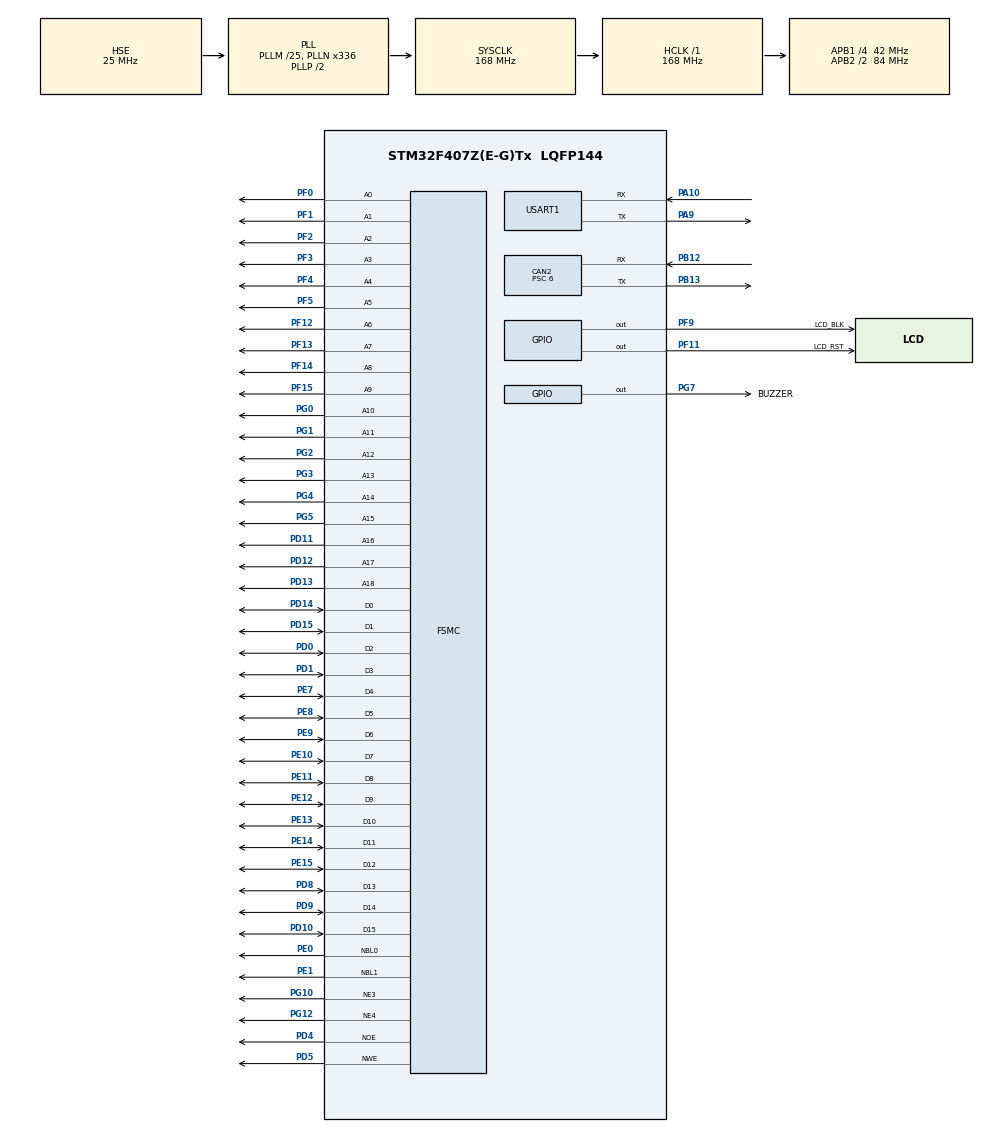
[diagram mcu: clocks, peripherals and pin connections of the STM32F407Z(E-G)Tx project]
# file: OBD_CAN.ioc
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CAN2.BS1=CAN_BS1_9TQ
CAN2.BS2=CAN_BS2_4TQ
CAN2.CalculateBaudRate=500000
CAN2.CalculateTimeBit=2000
CAN2.CalculateTimeQuantum=142.85714285714286
CAN2.Prescaler=6
Dma.MEMTOMEM.0.Direction=DMA_MEMORY_TO_MEMORY
Dma.MEMTOMEM.0.FIFOMode=DMA_FIFOMODE_ENABLE
Dma.MEMTOMEM.0.FIFOThreshold=DMA_FIFO_THRESHOLD_FULL
Dma.MEMTOMEM.0.Instance=DMA2_Stream0
Dma.MEMTOMEM.0.MemBurst=DMA_MBURST_SINGLE
Dma.MEMTOMEM.0.MemDataAlignment=DMA_MDATAALIGN_HALFWORD
Dma.MEMTOMEM.0.MemInc=DMA_MINC_DISABLE
Dma.MEMTOMEM.0.Mode=DMA_NORMAL
Dma.MEMTOMEM.0.PeriphBurst=DMA_PBURST_SINGLE
Dma.MEMTOMEM.0.PeriphDataAlignment=DMA_PDATAALIGN_HALFWORD
Dma.MEMTOMEM.0.PeriphInc=DMA_PINC_ENABLE
Dma.MEMTOMEM.0.Priority=DMA_PRIORITY_VERY_HIGH
Dma.Request0=MEMTOMEM
FSMC.AddressSetupTime3=5
FSMC.AddressSetupTime4=2
FSMC.BusTurnAroundDuration3=5
FSMC.BusTurnAroundDuration4=1
FSMC.DataSetupTime3=5
FSMC.DataSetupTime4=6
FSMC.WriteOperation4=FSMC_WRITE_OPERATION_ENABLE
Mcu.Family=STM32F4
Mcu.Name=STM32F407Z(E-G)Tx
Mcu.Package=LQFP144
NVIC.CAN2_RX0_IRQn=true\:5\:0\:true\:false\:true\:true\:true\:true
NVIC.CAN2_SCE_IRQn=true\:5\:0\:true\:false\:true\:true\:true\:true
NVIC.DMA2_Stream0_IRQn=true\:5\:0\:true\:false\:true\:true\:true\:true
NVIC.PriorityGroup=NVIC_PRIORITYGROUP_4
NVIC.TIM6_DAC_IRQn=true\:15\:0\:false\:false\:true\:false\:true\:true
NVIC.TimeBase=TIM6_DAC_IRQn
NVIC.TimeBaseIP=TIM6
PA10.Mode=Asynchronous
PA10.Signal=USART1_RX
PA13.Mode=Serial_Wire
PA13.Signal=SYS_JTMS-SWDIO
PA14.Mode=Serial_Wire
PA14.Signal=SYS_JTCK-SWCLK
PA9.Mode=Asynchronous
PA9.Signal=USART1_TX
PB12.Mode=CAN_Activate
PB12.Signal=CAN2_RX
PB13.Mode=CAN_Activate
PB13.Signal=CAN2_TX
PD0.Signal=FSMC_D2_DA2
PD1.Signal=FSMC_D3_DA3
PD10.Signal=FSMC_D15_DA15
PD11.Signal=FSMC_A16_CLE
PD12.Signal=FSMC_A17_ALE
PD13.Signal=FSMC_A18
PD14.Signal=FSMC_D0_DA0
PD15.Signal=FSMC_D1_DA1
PD4.Signal=FSMC_NOE
PD5.Signal=FSMC_NWE
PD8.Signal=FSMC_D13_DA13
PD9.Signal=FSMC_D14_DA14
PE0.Signal=FSMC_NBL0
PE1.Signal=FSMC_NBL1
PE10.Signal=FSMC_D7_DA7
PE11.Signal=FSMC_D8_DA8
PE12.Signal=FSMC_D9_DA9
PE13.Signal=FSMC_D10_DA10
PE14.Signal=FSMC_D11_DA11
PE15.Signal=FSMC_D12_DA12
PE7.Signal=FSMC_D4_DA4
PE8.Signal=FSMC_D5_DA5
PE9.Signal=FSMC_D6_DA6
PF0.Signal=FSMC_A0
PF1.Signal=FSMC_A1
PF11.GPIO_Label=LCD_RST
PF11.Signal=GPIO_Output
PF12.Signal=FSMC_A6
PF13.Signal=FSMC_A7
PF14.Signal=FSMC_A8
PF15.Signal=FSMC_A9
PF2.Signal=FSMC_A2
PF3.Signal=FSMC_A3
PF4.Signal=FSMC_A4
PF5.Signal=FSMC_A5
PF9.GPIO_Label=LCD_BLK
PF9.Signal=GPIO_Output
PG0.Signal=FSMC_A10
PG1.Signal=FSMC_A11
PG10.Mode=NorPsramChipSelect3_3
PG10.Signal=FSMC_NE3
PG12.Mode=NorPsramChipSelect4_4
PG12.Signal=FSMC_NE4
PG2.Signal=FSMC_A12
PG3.Signal=FSMC_A13
PG4.Signal=FSMC_A14
PG5.Signal=FSMC_A15
PG7.GPIO_Label=BUZZER
PG7.Signal=GPIO_Output
PH0-OSC_IN.Mode=HSE-External-Oscillator
PH0-OSC_IN.Signal=RCC_OSC_IN
PH1-OSC_OUT.Mode=HSE-External-Oscillator
PH1-OSC_OUT.Signal=RCC_OSC_OUT
ProjectManager.HeapSize=0x1000
ProjectManager.StackSize=0x1000
ProjectManager.TargetToolchain=MDK-ARM V5.32
RCC.48MHZClocksFreq_Value=84000000
RCC.AHBFreq_Value=168000000
RCC.APB1CLKDivider=RCC_HCLK_DIV4
RCC.APB1Freq_Value=42000000
RCC.APB1TimFreq_Value=84000000
RCC.APB2CLKDivider=RCC_HCLK_DIV2
RCC.APB2Freq_Value=84000000
RCC.APB2TimFreq_Value=168000000
RCC.CortexFreq_Value=168000000
RCC.HCLKFreq_Value=168000000
RCC.HSE_VALUE=25000000
RCC.HSI_VALUE=16000000
RCC.LSE_VALUE=32768
RCC.PLLM=25
RCC.PLLN=336
RCC.PLLSourceVirtual=RCC_PLLSOURCE_HSE
RCC.SYSCLKFreq_VALUE=168000000
RCC.SYSCLKSource=RCC_SYSCLKSOURCE_PLLCLK
RCC.VCOOutputFreq_Value=336000000
SH.FSMC_A0.0=FSMC_A0,A0_3
SH.FSMC_A0.1=FSMC_A0,19b-a4
SH.FSMC_A1.0=FSMC_A1,19b-a4
SH.FSMC_A10.0=FSMC_A10,19b-a4
SH.FSMC_A11.0=FSMC_A11,19b-a4
SH.FSMC_A12.0=FSMC_A12,19b-a4
SH.FSMC_A13.0=FSMC_A13,19b-a4
SH.FSMC_A14.0=FSMC_A14,19b-a4
SH.FSMC_A15.0=FSMC_A15,19b-a4
SH.FSMC_A16_CLE.0=FSMC_A16,19b-a4
SH.FSMC_A17_ALE.0=FSMC_A17,19b-a4
SH.FSMC_A18.0=FSMC_A18,19b-a4
SH.FSMC_A2.0=FSMC_A2,19b-a4
SH.FSMC_A3.0=FSMC_A3,19b-a4
SH.FSMC_A4.0=FSMC_A4,19b-a4
SH.FSMC_A5.0=FSMC_A5,19b-a4
SH.FSMC_A6.0=FSMC_A6,19b-a4
SH.FSMC_A7.0=FSMC_A7,19b-a4
SH.FSMC_A8.0=FSMC_A8,19b-a4
SH.FSMC_A9.0=FSMC_A9,19b-a4
SH.FSMC_D0_DA0.0=FSMC_D0,16b-d3
SH.FSMC_D0_DA0.1=FSMC_D0,16b-d4
SH.FSMC_D10_DA10.0=FSMC_D10,16b-d3
SH.FSMC_D10_DA10.1=FSMC_D10,16b-d4
SH.FSMC_D11_DA11.0=FSMC_D11,16b-d3
SH.FSMC_D11_DA11.1=FSMC_D11,16b-d4
SH.FSMC_D12_DA12.0=FSMC_D12,16b-d3
SH.FSMC_D12_DA12.1=FSMC_D12,16b-d4
SH.FSMC_D13_DA13.0=FSMC_D13,16b-d3
SH.FSMC_D13_DA13.1=FSMC_D13,16b-d4
SH.FSMC_D14_DA14.0=FSMC_D14,16b-d3
SH.FSMC_D14_DA14.1=FSMC_D14,16b-d4
SH.FSMC_D15_DA15.0=FSMC_D15,16b-d3
SH.FSMC_D15_DA15.1=FSMC_D15,16b-d4
SH.FSMC_D1_DA1.0=FSMC_D1,16b-d3
SH.FSMC_D1_DA1.1=FSMC_D1,16b-d4
SH.FSMC_D2_DA2.0=FSMC_D2,16b-d3
SH.FSMC_D2_DA2.1=FSMC_D2,16b-d4
SH.FSMC_D3_DA3.0=FSMC_D3,16b-d3
SH.FSMC_D3_DA3.1=FSMC_D3,16b-d4
SH.FSMC_D4_DA4.0=FSMC_D4,16b-d3
SH.FSMC_D4_DA4.1=FSMC_D4,16b-d4
SH.FSMC_D5_DA5.0=FSMC_D5,16b-d3
SH.FSMC_D5_DA5.1=FSMC_D5,16b-d4
SH.FSMC_D6_DA6.0=FSMC_D6,16b-d3
SH.FSMC_D6_DA6.1=FSMC_D6,16b-d4
SH.FSMC_D7_DA7.0=FSMC_D7,16b-d3
SH.FSMC_D7_DA7.1=FSMC_D7,16b-d4
SH.FSMC_D8_DA8.0=FSMC_D8,16b-d3
SH.FSMC_D8_DA8.1=FSMC_D8,16b-d4
SH.FSMC_D9_DA9.0=FSMC_D9,16b-d3
SH.FSMC_D9_DA9.1=FSMC_D9,16b-d4
SH.FSMC_NBL0.0=FSMC_NBL0,2ByteEnable4
SH.FSMC_NBL1.0=FSMC_NBL1,2ByteEnable4
SH.FSMC_NOE.0=FSMC_NOE,Lcd3
SH.FSMC_NOE.1=FSMC_NOE,Sram4
SH.FSMC_NWE.0=FSMC_NWE,Lcd3
SH.FSMC_NWE.1=FSMC_NWE,Sram4
USART1.VirtualMode=VM_ASYNC
VP_SYS_VS_tim6.Mode=TIM6
board=custom

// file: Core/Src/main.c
/* USER CODE BEGIN Header */
// ... ���һЩ�ļ�ͷ˵�� ...
/* USER CODE END Header */
#include "main.h"
#include "can.h"
#include "dma.h"
#include "usart.h"
#include "gpio.h"
#include "fsmc.h"
/* USER CODE BEGIN Includes */
#include "app_system.h" //
#include <stdio.h>
/* USER CODE END Includes */

/* USER CODE BEGIN PTD */
int fputc(int ch, FILE *f)
{
    HAL_UART_Transmit(&huart1, (uint8_t *)&ch, 1, HAL_MAX_DELAY);
    return ch;
}
/* USER CODE END PTD */

/* USER CODE BEGIN PFP */
void SystemClock_Config(void);
/* USER CODE END PFP */

int main(void)
{
  /* MCU Configuration--------------------------------------------------------*/
  HAL_Init();
  SystemClock_Config();

  /* Initialize all configured peripherals */
  MX_GPIO_Init();
  MX_DMA_Init();
  MX_USART1_UART_Init();  // 串口在这里才初始化成功！
  MX_FSMC_Init();
  MX_CAN2_Init();

  /* USER CODE BEGIN 2 */

  App_System_Init();
  vTaskStartScheduler();
  /* USER CODE END 2 */

  /* Infinite loop */
  while (1)
  {
  }
}
void SystemClock_Config(void)
{
  RCC_OscInitTypeDef RCC_OscInitStruct = {0};
  RCC_ClkInitTypeDef RCC_ClkInitStruct = {0};

  /** Configure the main internal regulator output voltage
  */
  __HAL_RCC_PWR_CLK_ENABLE();
  __HAL_PWR_VOLTAGESCALING_CONFIG(PWR_REGULATOR_VOLTAGE_SCALE1);

  /** Initializes the RCC Oscillators according to the specified parameters
  * in the RCC_OscInitTypeDef structure.
  */
  RCC_OscInitStruct.OscillatorType = RCC_OSCILLATORTYPE_HSE;
  RCC_OscInitStruct.HSEState = RCC_HSE_ON;
  RCC_OscInitStruct.PLL.PLLState = RCC_PLL_ON;
  RCC_OscInitStruct.PLL.PLLSource = RCC_PLLSOURCE_HSE;
  RCC_OscInitStruct.PLL.PLLM = 25;
  RCC_OscInitStruct.PLL.PLLN = 336;
  RCC_OscInitStruct.PLL.PLLP = RCC_PLLP_DIV2;
  RCC_OscInitStruct.PLL.PLLQ = 4;
  if (HAL_RCC_OscConfig(&RCC_OscInitStruct) != HAL_OK)
  {
    Error_Handler();
  }

  /** Initializes the CPU, AHB and APB buses clocks
  */
  RCC_ClkInitStruct.ClockType = RCC_CLOCKTYPE_HCLK|RCC_CLOCKTYPE_SYSCLK
                              |RCC_CLOCKTYPE_PCLK1|RCC_CLOCKTYPE_PCLK2;
  RCC_ClkInitStruct.SYSCLKSource = RCC_SYSCLKSOURCE_PLLCLK;
  RCC_ClkInitStruct.AHBCLKDivider = RCC_SYSCLK_DIV1;
  RCC_ClkInitStruct.APB1CLKDivider = RCC_HCLK_DIV4;
  RCC_ClkInitStruct.APB2CLKDivider = RCC_HCLK_DIV2;

  if (HAL_RCC_ClockConfig(&RCC_ClkInitStruct, FLASH_LATENCY_5) != HAL_OK)
  {
    Error_Handler();
  }
}

void HAL_TIM_PeriodElapsedCallback(TIM_HandleTypeDef *htim)
{
  if (htim->Instance == TIM6) {
    HAL_IncTick();
  }
}

void Error_Handler(void)
{
  __disable_irq();
  while (1)
  {
  }
}
